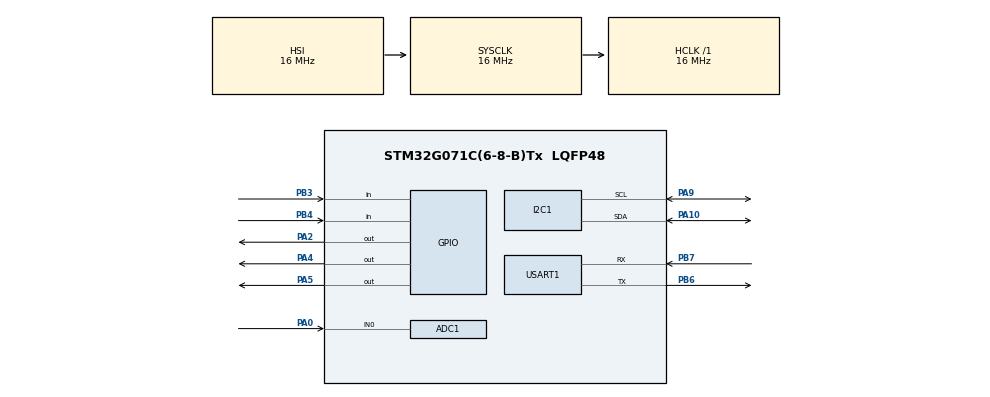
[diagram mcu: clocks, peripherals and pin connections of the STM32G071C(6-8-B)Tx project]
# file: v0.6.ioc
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ADC1.Channel-1\#ChannelRegularConversion=ADC_CHANNEL_0
ADC1.ClockPrescaler=ADC_CLOCK_ASYNC_DIV8
ADC1.NbrOfConversionFlag=1
ADC1.Rank-1\#ChannelRegularConversion=1
ADC1.SamplingTime-1\#ChannelRegularConversion=ADC_SAMPLINGTIME_COMMON_1
ADC1.SamplingTimeCommon1=ADC_SAMPLETIME_160CYCLES_5
ADC1.SamplingTimeCommon2=ADC_SAMPLETIME_160CYCLES_5
ADC1.SelectedChannel=ADC_CHANNEL_0
ADC1.master=1
Mcu.Family=STM32G0
Mcu.Name=STM32G071C(6-8-B)Tx
Mcu.Package=LQFP48
NVIC.TIM6_DAC_LPTIM1_IRQn=true\:0\:0\:false\:false\:true\:true\:true\:true
PA0.Mode=IN0
PA0.Signal=ADC1_IN0
PA10.GPIO_Pu=GPIO_PULLUP
PA10.Mode=I2C
PA10.Signal=I2C1_SDA
PA13.Mode=Serial_Wire
PA13.Signal=SYS_SWDIO
PA14-BOOT0.Mode=Serial_Wire
PA14-BOOT0.Signal=SYS_SWCLK
PA2.Signal=GPIO_Output
PA4.Signal=GPIO_Output
PA5.Signal=GPIO_Output
PA9.GPIO_Pu=GPIO_PULLUP
PA9.Mode=I2C
PA9.Signal=I2C1_SCL
PB3.Signal=GPIO_Input
PB4.Signal=GPIO_Input
PB5.Mode=SYS_WakeUp6
PB5.Signal=SYS_WKUP6
PB6.Mode=Asynchronous
PB6.Signal=USART1_TX
PB7.Mode=Asynchronous
PB7.Signal=USART1_RX
ProjectManager.HeapSize=0x200
ProjectManager.StackSize=0x400
ProjectManager.TargetToolchain=Makefile
RCC.AHBFreq_Value=16000000
RCC.CortexFreq_Value=16000000
RCC.EXTERNAL_CLOCK_VALUE=48000
RCC.HCLKFreq_Value=16000000
RCC.HSE_VALUE=8000000
RCC.HSI_VALUE=16000000
RCC.LSE_VALUE=32768
RCC.SYSCLKFreq_VALUE=16000000
RCC.VCOOutputFreq_Value=128000000
TIM3.Period=500-1
TIM3.Prescaler=16000-1
TIM6.Period=50000 - 1
TIM6.Prescaler=16-1
USART1.VirtualMode-Asynchronous=VM_ASYNC
VP_SYS_VS_DBSignals.Mode=DisableDeadBatterySignals
VP_TIM3_VS_ClockSourceINT.Mode=Internal
VP_TIM6_VS_ClockSourceINT.Mode=Enable_Timer
board=custom

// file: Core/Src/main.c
/* USER CODE BEGIN Header */
/**
  ******************************************************************************
  * @file           : main.c
  * @brief          : Main program body
  ******************************************************************************
  * @attention
  *
  * Copyright (c) 2023 STMicroelectronics.
  * All rights reserved.
  *
  * This software is licensed under terms that can be found in the LICENSE file
  * in the root directory of this software component.
  * If no LICENSE file comes with this software, it is provided AS-IS.
  *
  ******************************************************************************
  */
/* USER CODE END Header */
#include "main.h"

/* USER CODE BEGIN Includes */
#include "polaris.h"

/* USER CODE END Includes */

ADC_HandleTypeDef hadc1;

I2C_HandleTypeDef hi2c1;

TIM_HandleTypeDef htim3;
TIM_HandleTypeDef htim6;

UART_HandleTypeDef huart1;

void SystemClock_Config(void);
static void MX_GPIO_Init(void);
static void MX_I2C1_Init(void);
static void MX_TIM6_Init(void);
static void MX_USART1_UART_Init(void);
static void MX_TIM3_Init(void);
static void MX_ADC1_Init(void);

int main(void)
{

  /* MCU Configuration--------------------------------------------------------*/

  /* Reset of all peripherals, Initializes the Flash interface and the Systick. */
  HAL_Init();

  /* Configure the system clock */
  SystemClock_Config();

  /* Initialize all configured peripherals */
  MX_GPIO_Init();
  MX_I2C1_Init();
  MX_TIM6_Init();
  MX_USART1_UART_Init();
  MX_TIM3_Init();
  MX_ADC1_Init();
  /* USER CODE BEGIN 2 */

  Polaris_Init(&huart1);

  /* USER CODE END 2 */

  /* Infinite loop */
  /* USER CODE BEGIN WHILE */
  while (1)
  {
    Polaris_Update(&huart1);
    /* USER CODE END WHILE */

  }
}

void SystemClock_Config(void)
{
  RCC_OscInitTypeDef RCC_OscInitStruct = {0};
  RCC_ClkInitTypeDef RCC_ClkInitStruct = {0};

  /** Configure the main internal regulator output voltage
  */
  HAL_PWREx_ControlVoltageScaling(PWR_REGULATOR_VOLTAGE_SCALE1);

  /** Initializes the RCC Oscillators according to the specified parameters
  * in the RCC_OscInitTypeDef structure.
  */
  RCC_OscInitStruct.OscillatorType = RCC_OSCILLATORTYPE_HSI;
  RCC_OscInitStruct.HSIState = RCC_HSI_ON;
  RCC_OscInitStruct.HSIDiv = RCC_HSI_DIV1;
  RCC_OscInitStruct.HSICalibrationValue = RCC_HSICALIBRATION_DEFAULT;
  RCC_OscInitStruct.PLL.PLLState = RCC_PLL_NONE;
  if (HAL_RCC_OscConfig(&RCC_OscInitStruct) != HAL_OK)
  {
    Error_Handler();
  }

  /** Initializes the CPU, AHB and APB buses clocks
  */
  RCC_ClkInitStruct.ClockType = RCC_CLOCKTYPE_HCLK|RCC_CLOCKTYPE_SYSCLK
                              |RCC_CLOCKTYPE_PCLK1;
  RCC_ClkInitStruct.SYSCLKSource = RCC_SYSCLKSOURCE_HSI;
  RCC_ClkInitStruct.AHBCLKDivider = RCC_SYSCLK_DIV1;
  RCC_ClkInitStruct.APB1CLKDivider = RCC_HCLK_DIV1;

  if (HAL_RCC_ClockConfig(&RCC_ClkInitStruct, FLASH_LATENCY_0) != HAL_OK)
  {
    Error_Handler();
  }
}

static void MX_ADC1_Init(void)
{

  ADC_ChannelConfTypeDef sConfig = {0};

  /** Configure the global features of the ADC (Clock, Resolution, Data Alignment and number of conversion)
  */
  hadc1.Instance = ADC1;
  hadc1.Init.ClockPrescaler = ADC_CLOCK_ASYNC_DIV8;
  hadc1.Init.Resolution = ADC_RESOLUTION_12B;
  hadc1.Init.DataAlign = ADC_DATAALIGN_RIGHT;
  hadc1.Init.ScanConvMode = ADC_SCAN_DISABLE;
  hadc1.Init.EOCSelection = ADC_EOC_SINGLE_CONV;
  hadc1.Init.LowPowerAutoWait = DISABLE;
  hadc1.Init.LowPowerAutoPowerOff = DISABLE;
  hadc1.Init.ContinuousConvMode = DISABLE;
  hadc1.Init.NbrOfConversion = 1;
  hadc1.Init.DiscontinuousConvMode = DISABLE;
  hadc1.Init.ExternalTrigConv = ADC_SOFTWARE_START;
  hadc1.Init.ExternalTrigConvEdge = ADC_EXTERNALTRIGCONVEDGE_NONE;
  hadc1.Init.DMAContinuousRequests = DISABLE;
  hadc1.Init.Overrun = ADC_OVR_DATA_PRESERVED;
  hadc1.Init.SamplingTimeCommon1 = ADC_SAMPLETIME_160CYCLES_5;
  hadc1.Init.SamplingTimeCommon2 = ADC_SAMPLETIME_160CYCLES_5;
  hadc1.Init.OversamplingMode = DISABLE;
  hadc1.Init.TriggerFrequencyMode = ADC_TRIGGER_FREQ_HIGH;
  if (HAL_ADC_Init(&hadc1) != HAL_OK)
  {
    Error_Handler();
  }

  /** Configure Regular Channel
  */
  sConfig.Channel = ADC_CHANNEL_0;
  sConfig.Rank = ADC_REGULAR_RANK_1;
  sConfig.SamplingTime = ADC_SAMPLINGTIME_COMMON_1;
  if (HAL_ADC_ConfigChannel(&hadc1, &sConfig) != HAL_OK)
  {
    Error_Handler();
  }

}

static void MX_I2C1_Init(void)
{

  hi2c1.Instance = I2C1;
  hi2c1.Init.Timing = 0x00303D5B;
  hi2c1.Init.OwnAddress1 = 0;
  hi2c1.Init.AddressingMode = I2C_ADDRESSINGMODE_7BIT;
  hi2c1.Init.DualAddressMode = I2C_DUALADDRESS_DISABLE;
  hi2c1.Init.OwnAddress2 = 0;
  hi2c1.Init.OwnAddress2Masks = I2C_OA2_NOMASK;
  hi2c1.Init.GeneralCallMode = I2C_GENERALCALL_DISABLE;
  hi2c1.Init.NoStretchMode = I2C_NOSTRETCH_DISABLE;
  if (HAL_I2C_Init(&hi2c1) != HAL_OK)
  {
    Error_Handler();
  }

  /** Configure Analogue filter
  */
  if (HAL_I2CEx_ConfigAnalogFilter(&hi2c1, I2C_ANALOGFILTER_ENABLE) != HAL_OK)
  {
    Error_Handler();
  }

  /** Configure Digital filter
  */
  if (HAL_I2CEx_ConfigDigitalFilter(&hi2c1, 0) != HAL_OK)
  {
    Error_Handler();
  }

}

static void MX_TIM3_Init(void)
{

  TIM_ClockConfigTypeDef sClockSourceConfig = {0};
  TIM_MasterConfigTypeDef sMasterConfig = {0};

  htim3.Instance = TIM3;
  htim3.Init.Prescaler = 16000-1;
  htim3.Init.CounterMode = TIM_COUNTERMODE_UP;
  htim3.Init.Period = 500-1;
  htim3.Init.ClockDivision = TIM_CLOCKDIVISION_DIV1;
  htim3.Init.AutoReloadPreload = TIM_AUTORELOAD_PRELOAD_DISABLE;
  if (HAL_TIM_Base_Init(&htim3) != HAL_OK)
  {
    Error_Handler();
  }
  sClockSourceConfig.ClockSource = TIM_CLOCKSOURCE_INTERNAL;
  if (HAL_TIM_ConfigClockSource(&htim3, &sClockSourceConfig) != HAL_OK)
  {
    Error_Handler();
  }
  sMasterConfig.MasterOutputTrigger = TIM_TRGO_RESET;
  sMasterConfig.MasterSlaveMode = TIM_MASTERSLAVEMODE_DISABLE;
  if (HAL_TIMEx_MasterConfigSynchronization(&htim3, &sMasterConfig) != HAL_OK)
  {
    Error_Handler();
  }

}

static void MX_TIM6_Init(void)
{

  TIM_MasterConfigTypeDef sMasterConfig = {0};

  htim6.Instance = TIM6;
  htim6.Init.Prescaler = 16-1;
  htim6.Init.CounterMode = TIM_COUNTERMODE_UP;
  htim6.Init.Period = 50000 - 1;
  htim6.Init.AutoReloadPreload = TIM_AUTORELOAD_PRELOAD_DISABLE;
  if (HAL_TIM_Base_Init(&htim6) != HAL_OK)
  {
    Error_Handler();
  }
  sMasterConfig.MasterOutputTrigger = TIM_TRGO_RESET;
  sMasterConfig.MasterSlaveMode = TIM_MASTERSLAVEMODE_DISABLE;
  if (HAL_TIMEx_MasterConfigSynchronization(&htim6, &sMasterConfig) != HAL_OK)
  {
    Error_Handler();
  }

}

static void MX_USART1_UART_Init(void)
{

  huart1.Instance = USART1;
  huart1.Init.BaudRate = 115200;
  huart1.Init.WordLength = UART_WORDLENGTH_8B;
  huart1.Init.StopBits = UART_STOPBITS_1;
  huart1.Init.Parity = UART_PARITY_NONE;
  huart1.Init.Mode = UART_MODE_TX_RX;
  huart1.Init.HwFlowCtl = UART_HWCONTROL_NONE;
  huart1.Init.OverSampling = UART_OVERSAMPLING_16;
  huart1.Init.OneBitSampling = UART_ONE_BIT_SAMPLE_DISABLE;
  huart1.Init.ClockPrescaler = UART_PRESCALER_DIV1;
  huart1.AdvancedInit.AdvFeatureInit = UART_ADVFEATURE_NO_INIT;
  if (HAL_UART_Init(&huart1) != HAL_OK)
  {
    Error_Handler();
  }
  if (HAL_UARTEx_SetTxFifoThreshold(&huart1, UART_TXFIFO_THRESHOLD_1_8) != HAL_OK)
  {
    Error_Handler();
  }
  if (HAL_UARTEx_SetRxFifoThreshold(&huart1, UART_RXFIFO_THRESHOLD_1_8) != HAL_OK)
  {
    Error_Handler();
  }
  if (HAL_UARTEx_DisableFifoMode(&huart1) != HAL_OK)
  {
    Error_Handler();
  }

}

static void MX_GPIO_Init(void)
{
  GPIO_InitTypeDef GPIO_InitStruct = {0};

  /* GPIO Ports Clock Enable */
  __HAL_RCC_GPIOA_CLK_ENABLE();
  __HAL_RCC_GPIOB_CLK_ENABLE();

  /*Configure GPIO pin Output Level */
  HAL_GPIO_WritePin(GPIOA, GPIO_PIN_2|GPIO_PIN_4|GPIO_PIN_5, GPIO_PIN_RESET);

  /*Configure GPIO pins : PA2 PA4 PA5 */
  GPIO_InitStruct.Pin = GPIO_PIN_2|GPIO_PIN_4|GPIO_PIN_5;
  GPIO_InitStruct.Mode = GPIO_MODE_OUTPUT_PP;
  GPIO_InitStruct.Pull = GPIO_NOPULL;
  GPIO_InitStruct.Speed = GPIO_SPEED_FREQ_LOW;
  HAL_GPIO_Init(GPIOA, &GPIO_InitStruct);

  /*Configure GPIO pins : PB3 PB4 */
  GPIO_InitStruct.Pin = GPIO_PIN_3|GPIO_PIN_4;
  GPIO_InitStruct.Mode = GPIO_MODE_INPUT;
  GPIO_InitStruct.Pull = GPIO_NOPULL;
  HAL_GPIO_Init(GPIOB, &GPIO_InitStruct);

}

void Error_Handler(void)
{
  __disable_irq();
  while (1)
  {
  }
}
